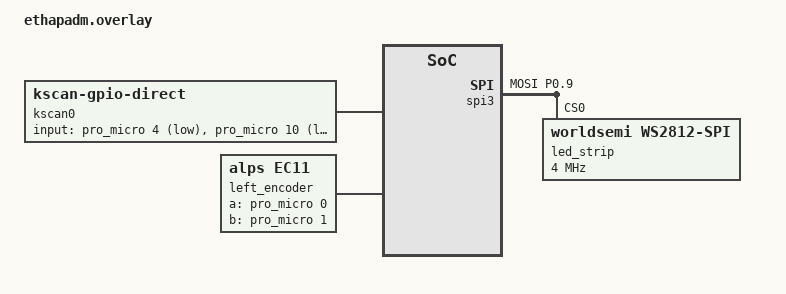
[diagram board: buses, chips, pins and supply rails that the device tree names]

#include <dt-bindings/led/led.h>

&pinctrl {
    spi3_default: spi3_default {
        group1 {
            psels = <NRF_PSEL(SPIM_MOSI, 0, 9)>;
        };
    };

    spi3_sleep: spi3_sleep {
        group1 {
            psels = <NRF_PSEL(SPIM_MOSI, 0, 9)>;
            low-power-enable;
        };
    };
};

&spi3 {
    compatible = "nordic,nrf-spim";
    status = "okay";

    pinctrl-0 = <&spi3_default>;
    pinctrl-1 = <&spi3_sleep>;
    pinctrl-names = "default", "sleep";

    led_strip: ws2812@0 {
        compatible = "worldsemi,ws2812-spi";

        /* SPI */
        reg = <0>; /* ignored, but necessary for SPI bindings */
        spi-max-frequency = <4000000>;

        /* WS2812 */
        chain-length = <6>; /* Change this according to how many leds are on the strip */
        spi-one-frame = <0x70>;
        spi-zero-frame = <0x40>;
        color-mapping = <LED_COLOR_ID_GREEN LED_COLOR_ID_RED LED_COLOR_ID_BLUE>;
    };
};

/ {
    chosen {
        zmk,kscan = &kscan0;
	zmk,underglow = &led_strip;
    };

    kscan0: kscan {
	compatible = "zmk,kscan-gpio-direct";
	input-gpios
            = <&pro_micro 4 (GPIO_ACTIVE_LOW | GPIO_PULL_UP)>
            , <&pro_micro 10 (GPIO_ACTIVE_LOW | GPIO_PULL_UP)>
            , <&pro_micro 16 (GPIO_ACTIVE_LOW | GPIO_PULL_UP)>
            , <&pro_micro 14 (GPIO_ACTIVE_LOW | GPIO_PULL_UP)>
            , <&pro_micro 15 (GPIO_ACTIVE_LOW | GPIO_PULL_UP)>
	    , <&pro_micro 6 (GPIO_ACTIVE_LOW | GPIO_PULL_UP)>
            , <&pro_micro 7 (GPIO_ACTIVE_LOW | GPIO_PULL_UP)>
	    , <&pro_micro 8 (GPIO_ACTIVE_LOW | GPIO_PULL_UP)>
            ;

	};

	left_encoder: encoder_left {
		compatible = "alps,ec11";
		a-gpios = <&pro_micro 0 (GPIO_ACTIVE_HIGH | GPIO_PULL_UP)>;
		b-gpios = <&pro_micro 1 (GPIO_ACTIVE_HIGH | GPIO_PULL_UP)>;
	};


};
